AUTOSAR XML (schema 00046)
package /ComponentTypes
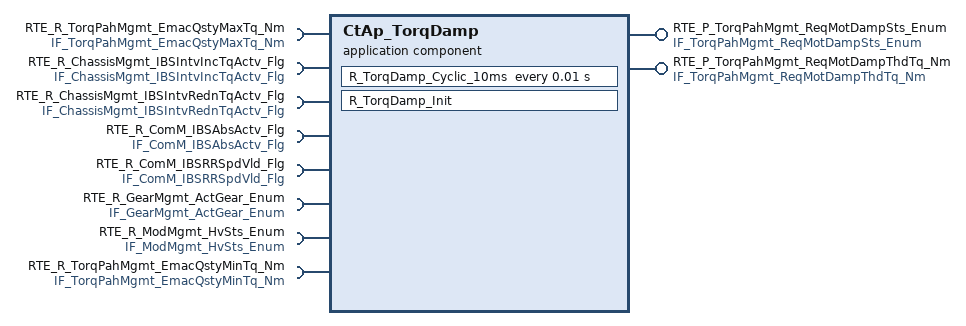
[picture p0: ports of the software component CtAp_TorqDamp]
  application sw component type CtAp_TorqDamp
    provide port RTE_P_TorqPahMgmt_ReqMotDampSts_Enum: nonqueued-sender-com-spec{data-element=tec_TorqPahMgmt_ReqMotDampSts_Enum, init-value=0}, provided-interface=IF_TorqPahMgmt_ReqMotDampSts_Enum
    require port RTE_R_TorqPahMgmt_EmacQstyMaxTq_Nm: nonqueued-receiver-com-spec{data-element=tec_TorqPahMgmt_EmacQstyMaxTq_Nm, filter=data-filter-type=ALWAYS, init-value=0}, required-interface=IF_TorqPahMgmt_EmacQstyMaxTq_Nm
    provide port RTE_P_TorqPahMgmt_ReqMotDampThdTq_Nm: nonqueued-sender-com-spec{data-element=tec_TorqPahMgmt_ReqMotDampThdTq_Nm, init-value=0}, provided-interface=IF_TorqPahMgmt_ReqMotDampThdTq_Nm
    7 x require port:
      RTE_R_ChassisMgmt_IBSIntvIncTqActv_Flg: nonqueued-receiver-com-spec{data-element=tec_ChassisMgmt_IBSIntvIncTqActv_Flg, filter=data-filter-type=ALWAYS, init-value=0}, required-interface=IF_ChassisMgmt_IBSIntvIncTqActv_Flg
      RTE_R_ChassisMgmt_IBSIntvRednTqActv_Flg: nonqueued-receiver-com-spec{data-element=tec_ChassisMgmt_IBSIntvRednTqActv_Flg, filter=data-filter-type=ALWAYS, init-value=0}, required-interface=IF_ChassisMgmt_IBSIntvRednTqActv_Flg
      RTE_R_ComM_IBSAbsActv_Flg: nonqueued-receiver-com-spec{data-element=tec_ComM_IBSAbsActv_Flg, filter=data-filter-type=ALWAYS, init-value=0}, required-interface=IF_ComM_IBSAbsActv_Flg
      RTE_R_ComM_IBSRRSpdVld_Flg: nonqueued-receiver-com-spec{data-element=tec_ComM_IBSRRSpdVld_Flg, filter=data-filter-type=ALWAYS, init-value=0}, required-interface=IF_ComM_IBSRRSpdVld_Flg
      RTE_R_GearMgmt_ActGear_Enum: nonqueued-receiver-com-spec{data-element=tec_GearMgmt_ActGear_Enum, filter=data-filter-type=ALWAYS, init-value=0}, required-interface=IF_GearMgmt_ActGear_Enum
      RTE_R_ModMgmt_HvSts_Enum: nonqueued-receiver-com-spec{data-element=tec_ModMgmt_HvSts_Enum, filter=data-filter-type=ALWAYS, init-value=0}, required-interface=IF_ModMgmt_HvSts_Enum
      RTE_R_TorqPahMgmt_EmacQstyMinTq_Nm: nonqueued-receiver-com-spec{data-element=tec_TorqPahMgmt_EmacQstyMinTq_Nm, filter=data-filter-type=ALWAYS, init-value=0}, required-interface=IF_TorqPahMgmt_EmacQstyMinTq_Nm
    behavior CtAp_TorqDamp_InternalBehavior
      init event CtAp_TorqDamp_InitEvent: start-on-event=R_TorqDamp_Init
      timing event TMT_R_TorqDamp_Cyclic_10ms: start-on-event=R_TorqDamp_Cyclic_10ms, period=0.01
      runnable R_TorqDamp_Init
      runnable R_TorqDamp_Cyclic_10ms
        data-receive-point-by-arguments:
          8 x access:
            REC_RTE_R_ChassisMgmt_IBSIntvIncTqActv_Flg_tec_ChassisMgmt_IBSIntvIncTqActv_Flg: accessed-variable=RTE_R_ChassisMgmt_IBSIntvIncTqActv_Flg.tec_ChassisMgmt_IBSIntvIncTqActv_Flg
            REC_RTE_R_ChassisMgmt_IBSIntvRednTqActv_Flg_tec_ChassisMgmt_IBSIntvRednTqActv_Flg: accessed-variable=RTE_R_ChassisMgmt_IBSIntvRednTqActv_Flg.tec_ChassisMgmt_IBSIntvRednTqActv_Flg
            REC_RTE_R_ComM_IBSAbsActv_Flg_tec_ComM_IBSAbsActv_Flg: accessed-variable=RTE_R_ComM_IBSAbsActv_Flg.tec_ComM_IBSAbsActv_Flg
            REC_RTE_R_Comm_IBSRRSpdVld_Flg_tec_ComM_IBSRRSpdVld_Flg: accessed-variable=RTE_R_ComM_IBSRRSpdVld_Flg.tec_ComM_IBSRRSpdVld_Flg
            REC_RTE_R_GearMgmt_ActGear_Enum_tec_GearMgmt_ActGear_Enum: accessed-variable=RTE_R_GearMgmt_ActGear_Enum.tec_GearMgmt_ActGear_Enum
            REC_RTE_R_ModMgmt_HvSts_Enum_tec_ModMgmt_HvSts_Enum: accessed-variable=RTE_R_ModMgmt_HvSts_Enum.tec_ModMgmt_HvSts_Enum
            REC_RTE_R_TorqPahMgmt_EmacQstyMaxTq_Nm_tec_TorqPahMgmt_EmacQstyMaxTq_Nm: accessed-variable=RTE_R_TorqPahMgmt_EmacQstyMaxTq_Nm.tec_TorqPahMgmt_EmacQstyMaxTq_Nm
            REC_RTE_R_TorqPahMgmt_EmacQstyMinTq_Nm_tec_TorqPahMgmt_EmacQstyMinTq_Nm: accessed-variable=RTE_R_TorqPahMgmt_EmacQstyMinTq_Nm.tec_TorqPahMgmt_EmacQstyMinTq_Nm
        data-send-points:
          access SEND_RTE_P_TorqPahMgmt_ReqMotDampSts_Enum_tec_TorqPahMgmt_ReqMotDampSts_Enum: accessed-variable=RTE_P_TorqPahMgmt_ReqMotDampSts_Enum.tec_TorqPahMgmt_ReqMotDampSts_Enum
          access SEND_RTE_P_TorqPahMgmt_ReqMotDampThdTq_Nm_tec_TorqPahMgmt_ReqMotDampThdTq_Nm: accessed-variable=RTE_P_TorqPahMgmt_ReqMotDampThdTq_Nm.tec_TorqPahMgmt_ReqMotDampThdTq_Nm
  swc implementation CtAp_TorqDamp_Implementation: behavior=CtAp_TorqDamp_InternalBehavior
    code-descriptors:
      code Default: artifact-descriptors=autosar-engineering-object={short-label=Default, category=SWOBJ}
